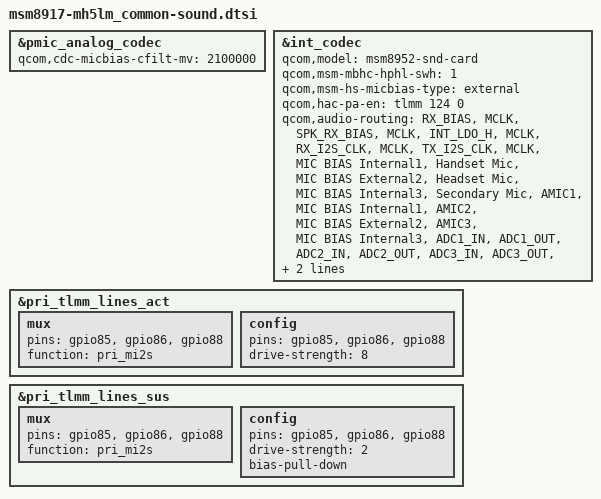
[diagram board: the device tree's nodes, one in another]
/*
 * Copyright (c) 2018, The Linux Foundation. All rights reserved.
 *
 * This program is free software; you can redistribute it and/or modify
 * it under the terms of the GNU General Public License version 2 and
 * only version 2 as published by the Free Software Foundation.
 *
 * This program is distributed in the hope that it will be useful,
 * but WITHOUT ANY WARRANTY; without even the implied warranty of
 * MERCHANTABILITY or FITNESS FOR A PARTICULAR PURPOSE.  See the
 * GNU General Public License for more details.
 */

&pmic_analog_codec {
    status = "okay";
    qcom,cdc-micbias-cfilt-mv = <2100000>;
};

&int_codec {
    status = "okay";
    qcom,model = "msm8952-snd-card";
    qcom,msm-mbhc-hphl-swh = <1>;
    qcom,msm-hs-micbias-type = "external";
    qcom,hac-pa-en = <&tlmm 124 0>;
    qcom,audio-routing =
        "RX_BIAS", "MCLK",
        "SPK_RX_BIAS", "MCLK",
        "INT_LDO_H", "MCLK",
        "RX_I2S_CLK", "MCLK",
        "TX_I2S_CLK", "MCLK",
        "MIC BIAS Internal1", "Handset Mic",
        "MIC BIAS External2", "Headset Mic",
        "MIC BIAS Internal3", "Secondary Mic",
        "AMIC1", "MIC BIAS Internal1",
        "AMIC2", "MIC BIAS External2",
        "AMIC3", "MIC BIAS Internal3",
        "ADC1_IN", "ADC1_OUT",
        "ADC2_IN", "ADC2_OUT",
        "ADC3_IN", "ADC3_OUT",
        "PDM_IN_RX1", "PDM_OUT_RX1",
        "PDM_IN_RX2", "PDM_OUT_RX2",
        "PDM_IN_RX3", "PDM_OUT_RX3";
};

&pri_tlmm_lines_act {
    mux {
        pins = "gpio85", "gpio86", "gpio88";
        function = "pri_mi2s";
    };

    config {
        pins = "gpio85", "gpio86", "gpio88";
        drive-strength = <8>;
    };
};


&pri_tlmm_lines_sus {
    mux {
        pins = "gpio85", "gpio86", "gpio88";
        function = "pri_mi2s";
    };

    config {
        pins = "gpio85", "gpio86", "gpio88";
        drive-strength = <2>;
        bias-pull-down;
    };
};

